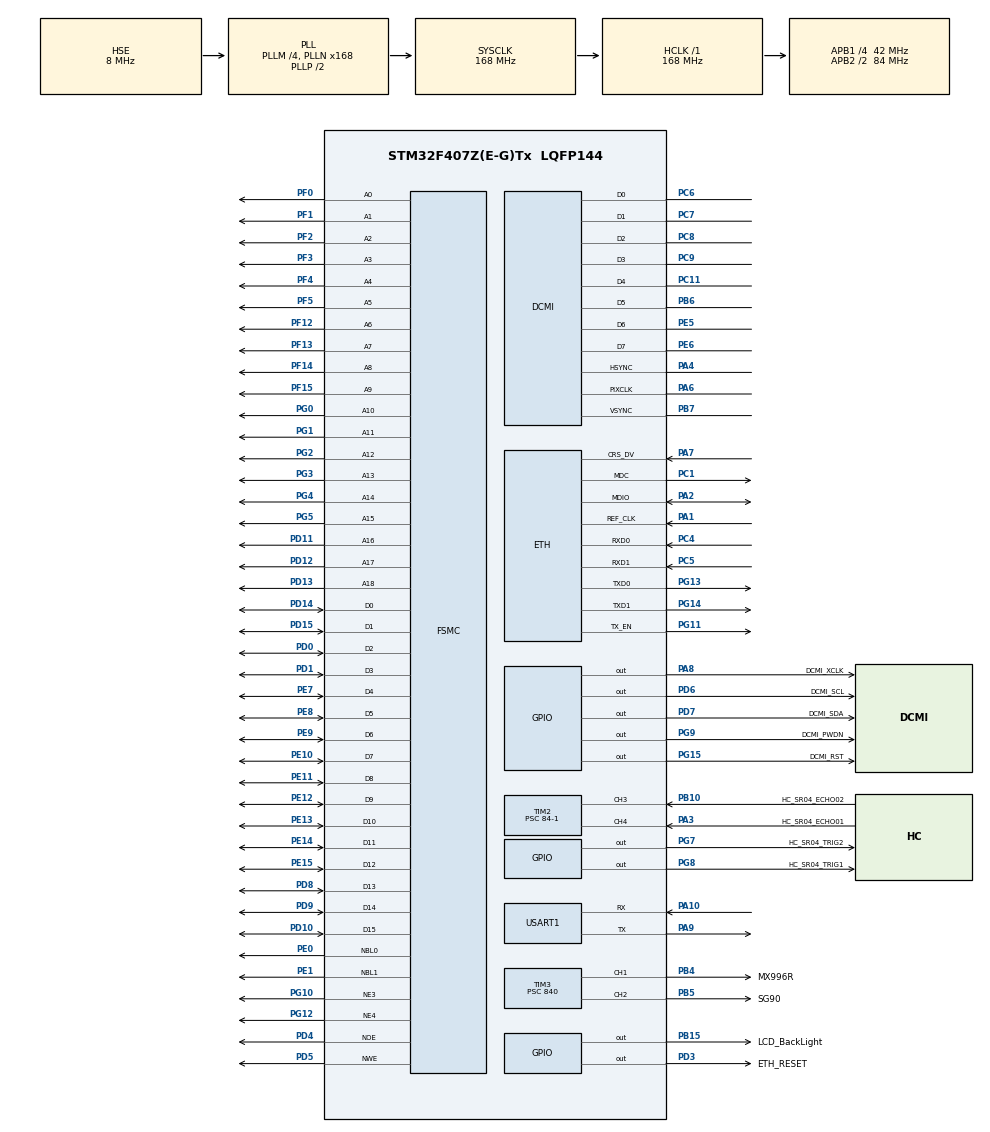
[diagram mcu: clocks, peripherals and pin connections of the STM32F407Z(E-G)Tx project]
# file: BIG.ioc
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DCMI.CaptureRate=DCMI_CR_ALL_FRAME
DCMI.JPEGMode=DCMI_JPEG_ENABLE
DCMI.PCKPolarity=DCMI_PCKPOLARITY_RISING
Dma.DCMI.0.Direction=DMA_PERIPH_TO_MEMORY
Dma.DCMI.0.FIFOMode=DMA_FIFOMODE_ENABLE
Dma.DCMI.0.FIFOThreshold=DMA_FIFO_THRESHOLD_HALFFULL
Dma.DCMI.0.Instance=DMA2_Stream1
Dma.DCMI.0.MemBurst=DMA_MBURST_SINGLE
Dma.DCMI.0.MemDataAlignment=DMA_MDATAALIGN_WORD
Dma.DCMI.0.MemInc=DMA_MINC_ENABLE
Dma.DCMI.0.Mode=DMA_CIRCULAR
Dma.DCMI.0.PeriphBurst=DMA_PBURST_SINGLE
Dma.DCMI.0.PeriphDataAlignment=DMA_PDATAALIGN_WORD
Dma.DCMI.0.PeriphInc=DMA_PINC_DISABLE
Dma.DCMI.0.Priority=DMA_PRIORITY_MEDIUM
Dma.Request0=DCMI
ETH.MediaInterface=ETH_MEDIA_INTERFACE_RMII
ETH.PHY_Name_RMII=userPHY
ETH.PHY_SR=0x1f
ETH.PHY_User_Name=LAN8720A
ETH.PhyAddress=0
FREERTOS.INCLUDE_xEventGroupSetBitFromISR=0
FREERTOS.INCLUDE_xTimerPendFunctionCall=0
FREERTOS.MEMORY_ALLOCATION=0
FREERTOS.Tasks01=defaultTask,0,512,StartDefaultTask,Default,NULL,Dynamic,NULL,NULL;ImageTransmissionTask,1,128,StartImageTransmissionTask,As external,NULL,Dynamic,NULL,NULL;LCDUITask,-2,128,StartLCDUITask,As external,NULL,Dynamic,NULL,NULL;CommunicateTask,2,128,StartCommunicateTask,As external,NULL,Dynamic,NULL,NULL;LitterDropTask,0,128,StartLitterDropTask,As external,NULL,Dynamic,NULL,NULL;MonitorTask,-1,128,StartMonitorTask,As external,NULL,Dynamic,NULL,NULL;GarbageDetectionTask,-1,128,StartGarbageDetectionTask,As external,NULL,Dynamic,NULL,NULL;UDPTXTask,1,256,StartUDPTXTask,As external,NULL,Dynamic,NULL,NULL;UDPRXTask,1,256,StartUDPRXTask,As external,NULL,Dynamic,NULL,NULL
FREERTOS.configLIBRARY_MAX_SYSCALL_INTERRUPT_PRIORITY=5
FREERTOS.configMAX_TASK_NAME_LEN=32
FREERTOS.configQUEUE_REGISTRY_SIZE=15
FREERTOS.configTOTAL_HEAP_SIZE=20480
FREERTOS.configUSE_COUNTING_SEMAPHORES=1
FREERTOS.configUSE_TIMERS=0
FSMC.AddressSetupTime1=0
FSMC.AddressSetupTime2=0xf
FSMC.BusTurnAroundDuration1=0
FSMC.BusTurnAroundDuration2=0
FSMC.DataSetupTime1=7
FSMC.DataSetupTime2=60
FSMC.ExtendedAddressSetupTime2=9
FSMC.ExtendedBusTurnAroundDuration2=0
FSMC.ExtendedDataSetupTime2=8
FSMC.ExtendedMode1=FSMC_EXTENDED_MODE_DISABLE
FSMC.ExtendedMode2=FSMC_EXTENDED_MODE_ENABLE
FSMC.WriteOperation1=FSMC_WRITE_OPERATION_ENABLE
LWIP.API_LIB_DEBUG=LWIP_DBG_OFF
LWIP.API_MSG_DEBUG=LWIP_DBG_OFF
LWIP.AUTOIP_DEBUG=LWIP_DBG_OFF
LWIP.DEFAULT_THREAD_PRIO=3
LWIP.DHCP6_DEBUG=LWIP_DBG_OFF
LWIP.DHCP_DEBUG=LWIP_DBG_OFF
LWIP.DNS_DEBUG=LWIP_DBG_OFF
LWIP.ETHARP_DEBUG=LWIP_DBG_OFF
LWIP.GATEWAY_ADDRESS=192.168.001.001
LWIP.HTTPD_DEBUG=LWIP_DBG_OFF
LWIP.HTTPD_DEBUG_TIMING=LWIP_DBG_OFF
LWIP.ICMP_DEBUG=LWIP_DBG_OFF
LWIP.IGMP_DEBUG=LWIP_DBG_OFF
LWIP.INET_DEBUG=LWIP_DBG_OFF
LWIP.IP6_DEBUG=LWIP_DBG_OFF
LWIP.IP_ADDRESS=192.168.001.115
LWIP.IP_DEBUG=LWIP_DBG_OFF
LWIP.IP_REASS_DEBUG=LWIP_DBG_OFF
LWIP.LWIP_DBG_MIN_LEVEL=LWIP_DBG_LEVEL_ALL
LWIP.LWIP_DBG_TYPES_ON=LWIP_DBG_OFF
LWIP.LWIP_DHCP=0
LWIP.LWIP_SOCKET_POLL=1
LWIP.LWIP_SOCKET_SELECT=1
LWIP.LWIP_TESTMODE=0
LWIP.LWIP_UDP=1
LWIP.MDNS_DEBUG=LWIP_DBG_OFF
LWIP.MEMP_DEBUG=LWIP_DBG_ON
LWIP.MEMP_NUM_TCP_PCB_LISTEN=8
LWIP.MEMP_NUM_TCP_SEG=16
LWIP.MEM_DEBUG=LWIP_DBG_ON
LWIP.MEM_SIZE=1600
LWIP.NETIF_DEBUG=LWIP_DBG_OFF
LWIP.NETMASK_ADDRESS=255.255.255.000
LWIP.PBUF_DEBUG=LWIP_DBG_ON
LWIP.PBUF_POOL_BUFSIZE=592
LWIP.PPP_DEBUG=LWIP_DBG_OFF
LWIP.RAW_DEBUG=LWIP_DBG_OFF
LWIP.SLIP_DEBUG=LWIP_DBG_OFF
LWIP.SMTP_DEBUG=LWIP_DBG_OFF
LWIP.SNMP_DEBUG=LWIP_DBG_OFF
LWIP.SNMP_MIB_DEBUG=LWIP_DBG_OFF
LWIP.SNTP_DEBUG=LWIP_DBG_OFF
LWIP.SOCKETS_DEBUG=LWIP_DBG_ON
LWIP.SYS_DEBUG=LWIP_DBG_ON
LWIP.TCPIP_DEBUG=LWIP_DBG_OFF
LWIP.TCPIP_THREAD_PRIO=3
LWIP.TCP_CWND_DEBUG=LWIP_DBG_OFF
LWIP.TCP_DEBUG=LWIP_DBG_OFF
LWIP.TCP_FR_DEBUG=LWIP_DBG_OFF
LWIP.TCP_INPUT_DEBUG=LWIP_DBG_OFF
LWIP.TCP_OUTPUT_DEBUG=LWIP_DBG_OFF
LWIP.TCP_QLEN_DEBUG=LWIP_DBG_OFF
LWIP.TCP_RST_DEBUG=LWIP_DBG_OFF
LWIP.TCP_RTO_DEBUG=LWIP_DBG_OFF
LWIP.TCP_TTL=255
LWIP.TCP_WND_DEBUG=LWIP_DBG_OFF
LWIP.TFTP_DEBUG=LWIP_DBG_OFF
LWIP.TIMERS_DEBUG=LWIP_DBG_OFF
LWIP.UDP_DEBUG=LWIP_DBG_ON
LWIP.Version=v2.1.2_Cube
Mcu.Family=STM32F4
Mcu.Name=STM32F407Z(E-G)Tx
Mcu.Package=LQFP144
NVIC.DCMI_IRQn=true\:1\:0\:true\:false\:true\:false\:true\:true
NVIC.DMA2_Stream1_IRQn=true\:1\:0\:true\:false\:true\:false\:false\:true
NVIC.ETH_IRQn=true\:5\:0\:true\:false\:true\:true\:true\:true
NVIC.PriorityGroup=NVIC_PRIORITYGROUP_4
NVIC.TIM2_IRQn=true\:5\:0\:false\:false\:true\:true\:true\:true
NVIC.TIM3_IRQn=true\:5\:0\:true\:false\:true\:true\:true\:true
NVIC.TIM6_DAC_IRQn=true\:0\:0\:false\:false\:true\:false\:false\:true
NVIC.TimeBase=TIM6_DAC_IRQn
NVIC.TimeBaseIP=TIM6
PA1.Mode=RMII
PA1.Signal=ETH_REF_CLK
PA10.Mode=Asynchronous
PA10.Signal=USART1_RX
PA13.Mode=JTAG_4_pins
PA13.Signal=SYS_JTMS-SWDIO
PA14.Mode=JTAG_4_pins
PA14.Signal=SYS_JTCK-SWCLK
PA15.Mode=JTAG_4_pins
PA15.Signal=SYS_JTDI
PA2.Mode=RMII
PA2.Signal=ETH_MDIO
PA3.GPIO_Label=HC_SR04_ECHO01
PA3.GPIO_PuPd=GPIO_PULLDOWN
PA3.GPIO_Speed=GPIO_SPEED_FREQ_HIGH
PA3.Signal=S_TIM2_CH4
PA4.GPIO_PuPd=GPIO_PULLUP
PA4.GPIO_Speed=GPIO_SPEED_FREQ_HIGH
PA4.Mode=Slave_8_bits_External_Synchro
PA4.Signal=DCMI_HSYNC
PA6.GPIO_PuPd=GPIO_PULLUP
PA6.GPIO_Speed=GPIO_SPEED_FREQ_HIGH
PA6.Mode=Slave_8_bits_External_Synchro
PA6.Signal=DCMI_PIXCLK
PA7.Mode=RMII
PA7.Signal=ETH_CRS_DV
PA8.GPIO_Label=DCMI_XCLK
PA8.Signal=GPIO_Output
PA9.Mode=Asynchronous
PA9.Signal=USART1_TX
PB10.GPIO_Label=HC_SR04_ECHO02
PB10.GPIO_PuPd=GPIO_PULLDOWN
PB10.GPIO_Speed=GPIO_SPEED_FREQ_HIGH
PB10.Signal=S_TIM2_CH3
PB15.GPIO_Label=LCD_BackLight
PB15.GPIO_PuPd=GPIO_PULLUP
PB15.GPIO_Speed=GPIO_SPEED_FREQ_MEDIUM
PB15.Signal=GPIO_Output
PB3.Mode=JTAG_4_pins
PB3.Signal=SYS_JTDO-SWO
PB4.GPIO_Label=MX996R
PB4.GPIO_PuPd=GPIO_PULLUP
PB4.GPIO_Speed=GPIO_SPEED_FREQ_HIGH
PB4.Signal=S_TIM3_CH1
PB5.GPIO_Label=SG90
PB5.GPIO_PuPd=GPIO_PULLUP
PB5.GPIO_Speed=GPIO_SPEED_FREQ_HIGH
PB5.Signal=S_TIM3_CH2
PB6.GPIO_PuPd=GPIO_PULLUP
PB6.GPIO_Speed=GPIO_SPEED_FREQ_HIGH
PB6.Mode=Slave_8_bits_External_Synchro
PB6.Signal=DCMI_D5
PB7.GPIO_PuPd=GPIO_PULLUP
PB7.GPIO_Speed=GPIO_SPEED_FREQ_HIGH
PB7.Mode=Slave_8_bits_External_Synchro
PB7.Signal=DCMI_VSYNC
PC1.Mode=RMII
PC1.Signal=ETH_MDC
PC11.GPIO_PuPd=GPIO_PULLUP
PC11.GPIO_Speed=GPIO_SPEED_FREQ_HIGH
PC11.Mode=Slave_8_bits_External_Synchro
PC11.Signal=DCMI_D4
PC4.Mode=RMII
PC4.Signal=ETH_RXD0
PC5.Mode=RMII
PC5.Signal=ETH_RXD1
PC6.GPIO_PuPd=GPIO_PULLUP
PC6.GPIO_Speed=GPIO_SPEED_FREQ_HIGH
PC6.Mode=Slave_8_bits_External_Synchro
PC6.Signal=DCMI_D0
PC7.GPIO_PuPd=GPIO_PULLUP
PC7.GPIO_Speed=GPIO_SPEED_FREQ_HIGH
PC7.Mode=Slave_8_bits_External_Synchro
PC7.Signal=DCMI_D1
PC8.GPIO_PuPd=GPIO_PULLUP
PC8.GPIO_Speed=GPIO_SPEED_FREQ_HIGH
PC8.Mode=Slave_8_bits_External_Synchro
PC8.Signal=DCMI_D2
PC9.GPIO_PuPd=GPIO_PULLUP
PC9.GPIO_Speed=GPIO_SPEED_FREQ_HIGH
PC9.Mode=Slave_8_bits_External_Synchro
PC9.Signal=DCMI_D3
PD0.Signal=FSMC_D2_DA2
PD1.Signal=FSMC_D3_DA3
PD10.Signal=FSMC_D15_DA15
PD11.Signal=FSMC_A16_CLE
PD12.Signal=FSMC_A17_ALE
PD13.Signal=FSMC_A18
PD14.Signal=FSMC_D0_DA0
PD15.Signal=FSMC_D1_DA1
PD3.GPIO_Label=ETH_RESET
PD3.PinState=GPIO_PIN_SET
PD3.Signal=GPIO_Output
PD4.Signal=FSMC_NOE
PD5.Signal=FSMC_NWE
PD6.GPIO_Label=DCMI_SCL
PD6.GPIO_ModeDefaultOutputPP=GPIO_MODE_OUTPUT_PP
PD6.GPIO_PuPd=GPIO_PULLUP
PD6.GPIO_Speed=GPIO_SPEED_FREQ_HIGH
PD6.PinState=GPIO_PIN_SET
PD6.Signal=GPIO_Output
PD7.GPIO_Label=DCMI_SDA
PD7.GPIO_PuPd=GPIO_PULLUP
PD7.GPIO_Speed=GPIO_SPEED_FREQ_HIGH
PD7.PinState=GPIO_PIN_SET
PD7.Signal=GPIO_Output
PD8.Signal=FSMC_D13_DA13
PD9.Signal=FSMC_D14_DA14
PE0.Signal=FSMC_NBL0
PE1.Signal=FSMC_NBL1
PE10.Signal=FSMC_D7_DA7
PE11.Signal=FSMC_D8_DA8
PE12.Signal=FSMC_D9_DA9
PE13.Signal=FSMC_D10_DA10
PE14.Signal=FSMC_D11_DA11
PE15.Signal=FSMC_D12_DA12
PE5.GPIO_PuPd=GPIO_PULLUP
PE5.GPIO_Speed=GPIO_SPEED_FREQ_HIGH
PE5.Mode=Slave_8_bits_External_Synchro
PE5.Signal=DCMI_D6
PE6.GPIO_PuPd=GPIO_PULLUP
PE6.GPIO_Speed=GPIO_SPEED_FREQ_HIGH
PE6.Mode=Slave_8_bits_External_Synchro
PE6.Signal=DCMI_D7
PE7.Signal=FSMC_D4_DA4
PE8.Signal=FSMC_D5_DA5
PE9.Signal=FSMC_D6_DA6
PF0.Signal=FSMC_A0
PF1.Signal=FSMC_A1
PF12.Signal=FSMC_A6
PF13.Signal=FSMC_A7
PF14.Signal=FSMC_A8
PF15.Signal=FSMC_A9
PF2.Signal=FSMC_A2
PF3.Signal=FSMC_A3
PF4.Signal=FSMC_A4
PF5.Signal=FSMC_A5
PG0.Signal=FSMC_A10
PG1.Signal=FSMC_A11
PG10.Mode=NorPsramChipSelect3_1
PG10.Signal=FSMC_NE3
PG11.Mode=RMII
PG11.Signal=ETH_TX_EN
PG12.Mode=NorPsramChipSelect4_2
PG12.Signal=FSMC_NE4
PG13.Mode=RMII
PG13.Signal=ETH_TXD0
PG14.Mode=RMII
PG14.Signal=ETH_TXD1
PG15.GPIO_Label=DCMI_RST
PG15.GPIO_ModeDefaultOutputPP=GPIO_MODE_OUTPUT_PP
PG15.GPIO_PuPd=GPIO_PULLUP
PG15.GPIO_Speed=GPIO_SPEED_FREQ_HIGH
PG15.PinState=GPIO_PIN_SET
PG15.Signal=GPIO_Output
PG2.Signal=FSMC_A12
PG3.Signal=FSMC_A13
PG4.Signal=FSMC_A14
PG5.Signal=FSMC_A15
PG7.GPIO_Label=HC_SR04_TRIG2
PG7.GPIO_PuPd=GPIO_NOPULL
PG7.GPIO_Speed=GPIO_SPEED_FREQ_HIGH
PG7.PinState=GPIO_PIN_SET
PG7.Signal=GPIO_Output
PG8.GPIO_Label=HC_SR04_TRIG1
PG8.GPIO_Speed=GPIO_SPEED_FREQ_HIGH
PG8.PinState=GPIO_PIN_SET
PG8.Signal=GPIO_Output
PG9.GPIO_Label=DCMI_PWDN
PG9.GPIO_ModeDefaultOutputPP=GPIO_MODE_OUTPUT_PP
PG9.GPIO_PuPd=GPIO_PULLUP
PG9.GPIO_Speed=GPIO_SPEED_FREQ_HIGH
PG9.PinState=GPIO_PIN_SET
PG9.Signal=GPIO_Output
PH0-OSC_IN.Mode=HSE-External-Oscillator
PH0-OSC_IN.Signal=RCC_OSC_IN
PH1-OSC_OUT.Mode=HSE-External-Oscillator
PH1-OSC_OUT.Signal=RCC_OSC_OUT
ProjectManager.HeapSize=0x200
ProjectManager.StackSize=0x400
ProjectManager.TargetToolchain=MDK-ARM V5.27
RCC.48MHZClocksFreq_Value=84000000
RCC.AHBFreq_Value=168000000
RCC.APB1CLKDivider=RCC_HCLK_DIV4
RCC.APB1Freq_Value=42000000
RCC.APB1TimFreq_Value=84000000
RCC.APB2CLKDivider=RCC_HCLK_DIV2
RCC.APB2Freq_Value=84000000
RCC.APB2TimFreq_Value=168000000
RCC.CortexFreq_Value=168000000
RCC.HCLKFreq_Value=168000000
RCC.HSE_VALUE=8000000
RCC.HSI_VALUE=16000000
RCC.LSE_VALUE=32768
RCC.PLLM=4
RCC.PLLN=168
RCC.PLLSourceVirtual=RCC_PLLSOURCE_HSE
RCC.SYSCLKFreq_VALUE=168000000
RCC.SYSCLKSource=RCC_SYSCLKSOURCE_PLLCLK
RCC.VCOOutputFreq_Value=336000000
SH.FSMC_A0.0=FSMC_A0,19b-a1
SH.FSMC_A1.0=FSMC_A1,19b-a1
SH.FSMC_A10.0=FSMC_A10,19b-a1
SH.FSMC_A11.0=FSMC_A11,19b-a1
SH.FSMC_A12.0=FSMC_A12,19b-a1
SH.FSMC_A13.0=FSMC_A13,19b-a1
SH.FSMC_A14.0=FSMC_A14,19b-a1
SH.FSMC_A15.0=FSMC_A15,19b-a1
SH.FSMC_A16_CLE.0=FSMC_A16,19b-a1
SH.FSMC_A17_ALE.0=FSMC_A17,19b-a1
SH.FSMC_A18.0=FSMC_A18,19b-a1
SH.FSMC_A2.0=FSMC_A2,19b-a1
SH.FSMC_A3.0=FSMC_A3,19b-a1
SH.FSMC_A4.0=FSMC_A4,19b-a1
SH.FSMC_A5.0=FSMC_A5,19b-a1
SH.FSMC_A6.0=FSMC_A6,19b-a1
SH.FSMC_A6.1=FSMC_A6,A6_2
SH.FSMC_A7.0=FSMC_A7,19b-a1
SH.FSMC_A8.0=FSMC_A8,19b-a1
SH.FSMC_A9.0=FSMC_A9,19b-a1
SH.FSMC_D0_DA0.0=FSMC_D0,16b-d1
SH.FSMC_D0_DA0.1=FSMC_D0,16b-d2
SH.FSMC_D10_DA10.0=FSMC_D10,16b-d1
SH.FSMC_D10_DA10.1=FSMC_D10,16b-d2
SH.FSMC_D11_DA11.0=FSMC_D11,16b-d1
SH.FSMC_D11_DA11.1=FSMC_D11,16b-d2
SH.FSMC_D12_DA12.0=FSMC_D12,16b-d1
SH.FSMC_D12_DA12.1=FSMC_D12,16b-d2
SH.FSMC_D13_DA13.0=FSMC_D13,16b-d1
SH.FSMC_D13_DA13.1=FSMC_D13,16b-d2
SH.FSMC_D14_DA14.0=FSMC_D14,16b-d1
SH.FSMC_D14_DA14.1=FSMC_D14,16b-d2
SH.FSMC_D15_DA15.0=FSMC_D15,16b-d1
SH.FSMC_D15_DA15.1=FSMC_D15,16b-d2
SH.FSMC_D1_DA1.0=FSMC_D1,16b-d1
SH.FSMC_D1_DA1.1=FSMC_D1,16b-d2
SH.FSMC_D2_DA2.0=FSMC_D2,16b-d1
SH.FSMC_D2_DA2.1=FSMC_D2,16b-d2
SH.FSMC_D3_DA3.0=FSMC_D3,16b-d1
SH.FSMC_D3_DA3.1=FSMC_D3,16b-d2
SH.FSMC_D4_DA4.0=FSMC_D4,16b-d1
SH.FSMC_D4_DA4.1=FSMC_D4,16b-d2
SH.FSMC_D5_DA5.0=FSMC_D5,16b-d1
SH.FSMC_D5_DA5.1=FSMC_D5,16b-d2
SH.FSMC_D6_DA6.0=FSMC_D6,16b-d1
SH.FSMC_D6_DA6.1=FSMC_D6,16b-d2
SH.FSMC_D7_DA7.0=FSMC_D7,16b-d1
SH.FSMC_D7_DA7.1=FSMC_D7,16b-d2
SH.FSMC_D8_DA8.0=FSMC_D8,16b-d1
SH.FSMC_D8_DA8.1=FSMC_D8,16b-d2
SH.FSMC_D9_DA9.0=FSMC_D9,16b-d1
SH.FSMC_D9_DA9.1=FSMC_D9,16b-d2
SH.FSMC_NBL0.0=FSMC_NBL0,2ByteEnable1
SH.FSMC_NBL1.0=FSMC_NBL1,2ByteEnable1
SH.FSMC_NOE.0=FSMC_NOE,Sram1
SH.FSMC_NOE.1=FSMC_NOE,Lcd2
SH.FSMC_NWE.0=FSMC_NWE,Sram1
SH.FSMC_NWE.1=FSMC_NWE,Lcd2
SH.S_TIM2_CH3.0=TIM2_CH3,Input_Capture3_from_TI3
SH.S_TIM2_CH4.0=TIM2_CH4,Input_Capture4_from_TI4
SH.S_TIM3_CH1.0=TIM3_CH1,PWM Generation1 CH1
SH.S_TIM3_CH2.0=TIM3_CH2,PWM Generation2 CH2
TIM2.AutoReloadPreload=TIM_AUTORELOAD_PRELOAD_ENABLE
TIM2.Channel-Input_Capture3_from_TI3=TIM_CHANNEL_3
TIM2.Channel-Input_Capture4_from_TI4=TIM_CHANNEL_4
TIM2.Period=0xffffffff
TIM2.Prescaler=84-1
TIM3.AutoReloadPreload=TIM_AUTORELOAD_PRELOAD_DISABLE
TIM3.Channel-PWM\ Generation1\ CH1=TIM_CHANNEL_1
TIM3.Channel-PWM\ Generation2\ CH2=TIM_CHANNEL_2
TIM3.ClockDivision=TIM_CLOCKDIVISION_DIV1
TIM3.Period=2000-1
TIM3.Prescaler=840
TIM3.Pulse-PWM\ Generation1\ CH1=1000
TIM3.Pulse-PWM\ Generation2\ CH2=200
USART1.VirtualMode=VM_ASYNC
VP_FREERTOS_VS_CMSIS_V1.Mode=CMSIS_V1
VP_LWIP_VS_Enabled.Mode=Enabled
VP_SYS_VS_tim6.Mode=TIM6
VP_TIM2_VS_ClockSourceINT.Mode=Internal
VP_TIM3_VS_ClockSourceINT.Mode=Internal
board=custom

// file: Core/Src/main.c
/* USER CODE BEGIN Header */
/**
  ******************************************************************************
  * @file           : main.c
  * @brief          : Main program body
  ******************************************************************************
  * @attention
  *
  * <h2><center>&copy; Copyright (c) 2021 STMicroelectronics.
  * All rights reserved.</center></h2>
  *
  * This software component is licensed by ST under Ultimate Liberty license
  * SLA0044, the "License"; You may not use this file except in compliance with
  * the License. You may obtain a copy of the License at:
  *                             www.st.com/SLA0044
  *
  ******************************************************************************
  */
/* USER CODE END Header */
#include "main.h"
#include "cmsis_os.h"
#include "dcmi.h"
#include "dma.h"
#include "lwip.h"
#include "tim.h"
#include "usart.h"
#include "gpio.h"
#include "fsmc.h"

/* USER CODE BEGIN Includes */
#include "tcp.h"
#include "ip_addr.h"
#include "sockets.h"
#include "api.h"
#include "portmacro.h"
#include "HC_SR04.h"
#include "tim.h"
#include "dcmi.h"
/* USER CODE END Includes */

/* USER CODE BEGIN PTD */
typedef uint32_t    u32;
typedef uint16_t    u16;
typedef uint8_t     u8;
/* USER CODE END PTD */

/* USER CODE BEGIN PV */
extern u8 TIM2CH3_CAPTURE_STA; //输入捕获状态
extern u32 TIM2CH3_CAPTURE_VAL;//输入捕获值(TIM2/TIM5 是 32 位)
extern u8 TIM2CH4_CAPTURE_STA; //输入捕获状态
extern u32 TIM2CH4_CAPTURE_VAL;//输入捕获值(TIM2/TIM5 是 32 位)
int serverSocket = -1;

/* USER CODE END PV */

void SystemClock_Config(void);
void MX_FREERTOS_Init(void);

/* USER CODE BEGIN 0 */
int fputc(int c,FILE* pf)
{
	uint8_t ch = (uint8_t)(c & 0xff);
	HAL_UART_Transmit(&huart1, &ch, 1, 0xff);
	return c;
}

//err_t LWIP_TCP_ReceiveCallback(void *arg, struct tcp_pcb *tpcb,struct pbuf *p, err_t err)
//{
//	if(p != NULL)
//	{
//		tcp_write(tpcb,p->payload,p->len,TCP_WRITE_FLAG_COPY);
//		tcp_recved(tpcb,p->tot_len);
//		pbuf_free(p);
//	}
//	else
//	{
//		printf("close\r\n");
//		tcp_close(tpcb);
//	}
//	return ERR_OK;
//}
//err_t LWIP_TCP_AcceptCallback(void *arg, struct tcp_pcb *newpcb, err_t err)
//{
//	tcp_recv(newpcb, LWIP_TCP_ReceiveCallback);
//	return ERR_OK;
//}

//err_t LWIP_TCP_ConnectedCallback(void *arg, struct tcp_pcb *tpcb, err_t err)
//{
//	if(tpcb == NULL)
//	{
//		printf("connect error...%d\r\n",err);
//	}
//	else
//	{
//		tcp_recv(tpcb,LWIP_TCP_ReceiveCallback);
//		printf("connect\r\n");
//	}
//	return ERR_OK;
//}

//int LWIP_TCP_Server(uint16_t port)
//{
//	struct tcp_pcb *bTCP;
//	err_t retval;
//	bTCP = tcp_new();
//	if(bTCP == NULL)
//	{
//		printf("error");
//		return -1;
//	}
//	retval = tcp_bind(bTCP, IP_ADDR_ANY,port);
//	if(retval == ERR_OK)
//	{
//		bTCP = tcp_listen(bTCP);
//		if(bTCP == NULL)
//		{
//			printf("error");
//			return -1;
//		}
//		printf("...\r\n");
//		tcp_accept(bTCP,LWIP_TCP_AcceptCallback);
//		return 0;
//	}
//	memp_free(MEMP_TCP_PCB,bTCP);
//	printf("error");
//	return -1;
//}

//int LWIP_TCP_Client()
//{
//	struct tcp_pcb *bTCP;
////	err_t retval;
//	ip_addr_t tcp_server_ip;
//	bTCP = tcp_new();
//	if(bTCP == NULL)
//	{
//		return -1;
//	}
//	IP_ADDR4(&tcp_server_ip,192,168,1,150);
//	tcp_connect(bTCP,&tcp_server_ip,667,LWIP_TCP_ConnectedCallback);
//	return 0;
//}

/* USER CODE END 0 */

int main(void)
{

  /* MCU Configuration--------------------------------------------------------*/

  /* Reset of all peripherals, Initializes the Flash interface and the Systick. */
  HAL_Init();

  /* USER CODE BEGIN Init */
  delay_init(168);
  /* USER CODE END Init */

  /* Configure the system clock */
  SystemClock_Config();

  /* USER CODE BEGIN SysInit */
//	delay_init(168);  //初始化延时函数
  /* USER CODE END SysInit */

  /* Initialize all configured peripherals */
  MX_GPIO_Init();
  MX_DMA_Init();
  MX_USART1_UART_Init();
  MX_DCMI_Init();
  MX_FSMC_Init();
  MX_TIM3_Init();
  MX_TIM2_Init();
  /* USER CODE BEGIN 2 */

//  LWIP_TCP_Server(666);
//  LWIP_TCP_Client();
  /* USER CODE END 2 */

  /* Call init function for freertos objects (in freertos.c) */
  MX_FREERTOS_Init();
  /* Start scheduler */
  osKernelStart();

  /* We should never get here as control is now taken by the scheduler */
  /* Infinite loop */
  /* USER CODE BEGIN WHILE */
  while (1)
  {
//	MX_LWIP_Process();
    /* USER CODE END WHILE */

  }
}

void SystemClock_Config(void)
{
  RCC_OscInitTypeDef RCC_OscInitStruct = {0};
  RCC_ClkInitTypeDef RCC_ClkInitStruct = {0};

  /** Configure the main internal regulator output voltage
  */
  __HAL_RCC_PWR_CLK_ENABLE();
  __HAL_PWR_VOLTAGESCALING_CONFIG(PWR_REGULATOR_VOLTAGE_SCALE1);
  /** Initializes the RCC Oscillators according to the specified parameters
  * in the RCC_OscInitTypeDef structure.
  */
  RCC_OscInitStruct.OscillatorType = RCC_OSCILLATORTYPE_HSE;
  RCC_OscInitStruct.HSEState = RCC_HSE_ON;
  RCC_OscInitStruct.PLL.PLLState = RCC_PLL_ON;
  RCC_OscInitStruct.PLL.PLLSource = RCC_PLLSOURCE_HSE;
  RCC_OscInitStruct.PLL.PLLM = 4;
  RCC_OscInitStruct.PLL.PLLN = 168;
  RCC_OscInitStruct.PLL.PLLP = RCC_PLLP_DIV2;
  RCC_OscInitStruct.PLL.PLLQ = 4;
  if (HAL_RCC_OscConfig(&RCC_OscInitStruct) != HAL_OK)
  {
    Error_Handler();
  }
  /** Initializes the CPU, AHB and APB buses clocks
  */
  RCC_ClkInitStruct.ClockType = RCC_CLOCKTYPE_HCLK|RCC_CLOCKTYPE_SYSCLK
                              |RCC_CLOCKTYPE_PCLK1|RCC_CLOCKTYPE_PCLK2;
  RCC_ClkInitStruct.SYSCLKSource = RCC_SYSCLKSOURCE_PLLCLK;
  RCC_ClkInitStruct.AHBCLKDivider = RCC_SYSCLK_DIV1;
  RCC_ClkInitStruct.APB1CLKDivider = RCC_HCLK_DIV4;
  RCC_ClkInitStruct.APB2CLKDivider = RCC_HCLK_DIV2;

  if (HAL_RCC_ClockConfig(&RCC_ClkInitStruct, FLASH_LATENCY_5) != HAL_OK)
  {
    Error_Handler();
  }
}

 /**
  * @brief  Period elapsed callback in non blocking mode
  * @note   This function is called  when TIM6 interrupt took place, inside
  * HAL_TIM_IRQHandler(). It makes a direct call to HAL_IncTick() to increment
  * a global variable "uwTick" used as application time base.
  * @param  htim : TIM handle
  * @retval None
  */
void HAL_TIM_PeriodElapsedCallback(TIM_HandleTypeDef *htim)
{
  /* USER CODE BEGIN Callback 0 */

if(htim->Instance == TIM2)
	{
		if(htim->Channel == HAL_TIM_ACTIVE_CHANNEL_3)
		{
			if((TIM2CH3_CAPTURE_STA&0X80)==0)//还未成功捕获
			{
				if(TIM2CH3_CAPTURE_STA&0X40)//已经捕获到高电平了
				{
					if((TIM2CH3_CAPTURE_STA&0X3F)==0X3F)//高电平太长了
					{
						TIM2CH3_CAPTURE_STA|=0X80; //标记成功捕获了一次
						TIM2CH3_CAPTURE_VAL=0XFFFFFFFF;
					}else TIM2CH3_CAPTURE_STA++;
				}
			}
		}
		else if(htim->Channel == HAL_TIM_ACTIVE_CHANNEL_4)
		{
			if((TIM2CH4_CAPTURE_STA&0X80)==0)//还未成功捕获
			{
				if(TIM2CH4_CAPTURE_STA&0X40)//已经捕获到高电平了
				{
					if((TIM2CH4_CAPTURE_STA&0X3F)==0X3F)//高电平太长了
					{
						TIM2CH4_CAPTURE_STA|=0X80; //标记成功捕获了一次
						TIM2CH4_CAPTURE_VAL=0XFFFFFFFF;
					}else TIM2CH4_CAPTURE_STA++;
				}
			}
		}
	}
  /* USER CODE END Callback 0 */
  if (htim->Instance == TIM6) {
    HAL_IncTick();
  }
}

void Error_Handler(void)
{
  __disable_irq();
  while (1)
  {
  }
}

/************************ (C) COPYRIGHT STMicroelectronics *****END OF FILE****/

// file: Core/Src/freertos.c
/* USER CODE BEGIN Header */
/**
  ******************************************************************************
  * File Name          : freertos.c
  * Description        : Code for freertos applications
  ******************************************************************************
  * @attention
  *
  * <h2><center>&copy; Copyright (c) 2021 STMicroelectronics.
  * All rights reserved.</center></h2>
  *
  * This software component is licensed by ST under Ultimate Liberty license
  * SLA0044, the "License"; You may not use this file except in compliance with
  * the License. You may obtain a copy of the License at:
  *                             www.st.com/SLA0044
  *
  ******************************************************************************
  */
/* USER CODE END Header */

#include "FreeRTOS.h"
#include "task.h"
#include "main.h"
#include "cmsis_os.h"

/* USER CODE BEGIN Includes */
#include "FreeRTOS_Tasks.h"
#include "malloc.h"
#include "tcp.h"
#include "string.h"
#include "api.h"
#include "sockets.h"
/* USER CODE END Includes */

/* USER CODE BEGIN Variables */
struct garbagePercentageType garbagePercentage;
EventGroupHandle_t EventGroupHandler;
BaseType_t HigherPriorityTaskWoken;

u8 UDP_FLAG;
u32 *jpeg_buf0;							//JPEG数据缓存buf,通过malloc申请内存
u32 *jpeg_buf1;							//JPEG数据缓存buf,通过malloc申请内存
u32 *jpeg_data_buf;						//JPEG数据缓存buf,通过malloc申请内存

int sock;                          //UDP Socket变量
u8 *TX_buf;                  //发送缓冲区
struct sockaddr_in udp_addr,seraddr;    //UDP Socket、UDP服务器描述符
socklen_t addrlen;
/* USER CODE END Variables */
osThreadId defaultTaskHandle;
osThreadId ImageTransmissionTaskHandle;
osThreadId LCDUITaskHandle;
osThreadId CommunicateTaskHandle;
osThreadId LitterDropTaskHandle;
osThreadId MonitorTaskHandle;
osThreadId GarbageDetectionTaskHandle;
osThreadId UDPTXTaskHandle;
osThreadId UDPRXTaskHandle;

void StartDefaultTask(void const * argument);
extern void StartImageTransmissionTask(void const * argument);
extern void StartLCDUITask(void const * argument);
extern void StartCommunicateTask(void const * argument);
extern void StartLitterDropTask(void const * argument);
extern void StartMonitorTask(void const * argument);
extern void StartGarbageDetectionTask(void const * argument);
extern void StartUDPTXTask(void const * argument);
extern void StartUDPRXTask(void const * argument);

extern void MX_LWIP_Init(void);
void MX_FREERTOS_Init(void); /* (MISRA C 2004 rule 8.1) */

void MX_FREERTOS_Init(void) {
  /* USER CODE BEGIN Init */
	EventGroupHandler = xEventGroupCreate();//创建事件标志组
	xEventGroupSetBits(EventGroupHandler,GARBAGE_DISPOSE_FINISH_EVENTBIT);
	my_mem_init(SRAMIN);			//初始化内部内存池
	my_mem_init(SRAMEX);			//初始化外部内存池
	my_mem_init(SRAMCCM);			//初始化CCM内存池
	printf("sram 初始化完成\r\n");
	TX_buf = pvPortMalloc(FRAME_SIZE + sizeof(struct transfertype));

	printf("sramin:buf0:%x,buf1:%x\r\n",jpeg_buf0,jpeg_buf1);
	printf("%d",TX_buf);
	jpeg_data_buf = mymalloc(SRAMEX,300*1024);		//为jpeg文件申请内存(最大300KB)
	printf("sramex:%d\r\n",jpeg_data_buf);
	UDP_FLAG = 0;
  /* USER CODE END Init */

  /* Create the thread(s) */
  /* definition and creation of defaultTask */
  osThreadDef(defaultTask, StartDefaultTask, osPriorityNormal, 0, 512);
  defaultTaskHandle = osThreadCreate(osThread(defaultTask), NULL);

  /* definition and creation of ImageTransmissionTask */
  osThreadDef(ImageTransmissionTask, StartImageTransmissionTask, osPriorityAboveNormal, 0, 128);
  ImageTransmissionTaskHandle = osThreadCreate(osThread(ImageTransmissionTask), NULL);

  /* definition and creation of LCDUITask */
  osThreadDef(LCDUITask, StartLCDUITask, osPriorityLow, 0, 128);
  LCDUITaskHandle = osThreadCreate(osThread(LCDUITask), NULL);

  /* definition and creation of CommunicateTask */
  osThreadDef(CommunicateTask, StartCommunicateTask, osPriorityHigh, 0, 128);
  CommunicateTaskHandle = osThreadCreate(osThread(CommunicateTask), NULL);

  /* definition and creation of LitterDropTask */
  osThreadDef(LitterDropTask, StartLitterDropTask, osPriorityNormal, 0, 128);
  LitterDropTaskHandle = osThreadCreate(osThread(LitterDropTask), NULL);

  /* definition and creation of MonitorTask */
  osThreadDef(MonitorTask, StartMonitorTask, osPriorityBelowNormal, 0, 128);
  MonitorTaskHandle = osThreadCreate(osThread(MonitorTask), NULL);

  /* definition and creation of GarbageDetectionTask */
  osThreadDef(GarbageDetectionTask, StartGarbageDetectionTask, osPriorityBelowNormal, 0, 128);
  GarbageDetectionTaskHandle = osThreadCreate(osThread(GarbageDetectionTask), NULL);

  /* definition and creation of UDPTXTask */
  osThreadDef(UDPTXTask, StartUDPTXTask, osPriorityAboveNormal, 0, 256);
  UDPTXTaskHandle = osThreadCreate(osThread(UDPTXTask), NULL);

  /* definition and creation of UDPRXTask */
  osThreadDef(UDPRXTask, StartUDPRXTask, osPriorityAboveNormal, 0, 256);
  UDPRXTaskHandle = osThreadCreate(osThread(UDPRXTask), NULL);

}

void StartDefaultTask(void const * argument)
{
  /* init code for LWIP */
  MX_LWIP_Init();
  /* USER CODE BEGIN StartDefaultTask */
  /* Infinite loop */
	jpeg_buf0 = pvPortMalloc(jpeg_dma_bufsize*4);	//为jpeg dma接收申请内存
	jpeg_buf1 = pvPortMalloc(jpeg_dma_bufsize*4);	//为jpeg dma接收申请内存
	int recv_data_len;
	EventBits_t CurrentEventGroupBit;
	memset(jpeg_buf0,3,jpeg_dma_bufsize*4);
	memset(jpeg_buf1,3,jpeg_dma_bufsize*4);
	printf("buf:%d\r\n",*jpeg_buf0);
	sock = -1;
	do{
		sock = socket(AF_INET,SOCK_DGRAM,0);
		printf("Socket error\r\n");
	}while(sock < 0);

	printf("Socket created!\r\n");

	udp_addr.sin_family = AF_INET;
	udp_addr.sin_addr.s_addr = INADDR_ANY;
	udp_addr.sin_port = htons(668);
	memset(&(udp_addr.sin_zero),0,sizeof(udp_addr.sin_zero));

	seraddr.sin_family = AF_INET;
	addrlen = sizeof(struct sockaddr_in);
	printf("sock:%d\r\n",sock);
	printf("addrlen:%d\r\n",addrlen);
	while(bind(sock,(struct sockaddr*)&udp_addr,sizeof(struct sockaddr)) == -1)
	{
		printf("Unable to bind\r\n");
	}
	printf("Bind Successful!\r\n");
	while(1)
	{
		if(!UDP_FLAG)
		{
			CurrentEventGroupBit = xEventGroupGetBits(EventGroupHandler);
			xEventGroupClearBits(EventGroupHandler,CurrentEventGroupBit);
			printf("defaulttask:sock:%d\r\n",sock);
			printf("defaulttask:addrlen:%d\r\n",addrlen);
			printf("default:%d",xEventGroupGetBits(EventGroupHandler));
			printf("default task:UDP initing...\r\n");
			recv_data_len = recvfrom(sock,RX_BUF,1024,0,(struct sockaddr*)&seraddr,&addrlen);
			printf("recv_data_len:%d\r\n",recv_data_len);
			if(recv_data_len > 0)
			{
				printf("received init sig\r\n");
				sendto(sock,RX_BUF,recv_data_len,0,(struct sockaddr*)&seraddr,addrlen);
				UDP_FLAG = 1;
				printf("UDP Init successful\r\n");
				xEventGroupSetBits(EventGroupHandler,CurrentEventGroupBit);
			}
		}
		else
		{
			printf("Default task: Nothing todo\r\n");
			vTaskDelay(1000);
		}
	}
  /* USER CODE END StartDefaultTask */
}

/************************ (C) COPYRIGHT STMicroelectronics *****END OF FILE****/
